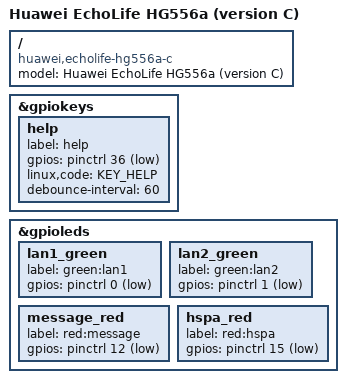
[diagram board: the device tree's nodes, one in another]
#include "bcm6358-huawei-echolife-hg556a.dtsi"

/ {
	model = "Huawei EchoLife HG556a (version C)";
	compatible = "huawei,echolife-hg556a-c", "brcm,bcm6358";
};

&gpiokeys {
	help {
		label = "help";
		gpios = <&pinctrl 36 1>;
		linux,code = <KEY_HELP>;
		debounce-interval = <60>;
	};
};

&gpioleds {
	lan1_green {
		label = "green:lan1";
		gpios = <&pinctrl 0 1>;
	};

	lan2_green {
		label = "green:lan2";
		gpios = <&pinctrl 1 1>;
	};

	message_red {
		label = "red:message";
		gpios = <&pinctrl 12 1>;
	};

	hspa_red {
		label = "red:hspa";
		gpios = <&pinctrl 15 1>;
	};
};
